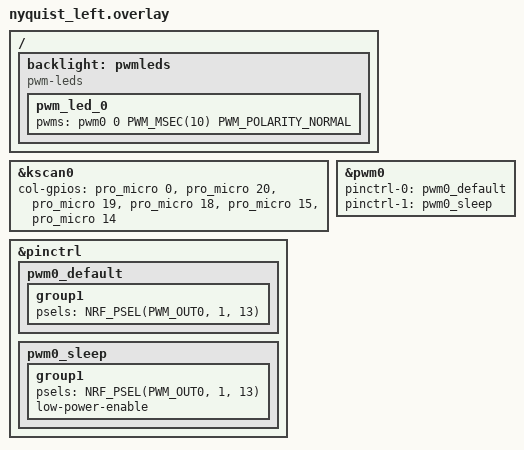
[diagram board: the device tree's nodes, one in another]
#include "nyquist.dtsi" // Notice that the main dtsi files are included in the overlay.

&kscan0 {
    col-gpios
        = <&pro_micro 0 GPIO_ACTIVE_HIGH> // col1 in the schematic
        , <&pro_micro 20 GPIO_ACTIVE_HIGH> // col2 in the schematic
        , <&pro_micro 19 GPIO_ACTIVE_HIGH> // col3 in the schematic
        , <&pro_micro 18 GPIO_ACTIVE_HIGH> // col4 in the schematic
        , <&pro_micro 15 GPIO_ACTIVE_HIGH> // col5 in the schematic
        , <&pro_micro 14 GPIO_ACTIVE_HIGH> // col6 in the schematic
        ;
};

&pinctrl {
    // Other pinctrl definitions for other hardware
    pwm0_default: pwm0_default {
        group1 {
            psels = <NRF_PSEL(PWM_OUT0, 1, 13)>;
        };
    };
    pwm0_sleep: pwm0_sleep {
        group1 {
            psels = <NRF_PSEL(PWM_OUT0, 1, 13)>;
            low-power-enable;
        };
    };
};

&pwm0 {
    status = "okay";
    pinctrl-0 = <&pwm0_default>;
    pinctrl-1 = <&pwm0_sleep>;
    pinctrl-names = "default", "sleep";
};

/ {
    backlight: pwmleds {
        compatible = "pwm-leds";
        pwm_led_0 {
            pwms = <&pwm0 0 PWM_MSEC(10) PWM_POLARITY_NORMAL>;
        };
    };
};
